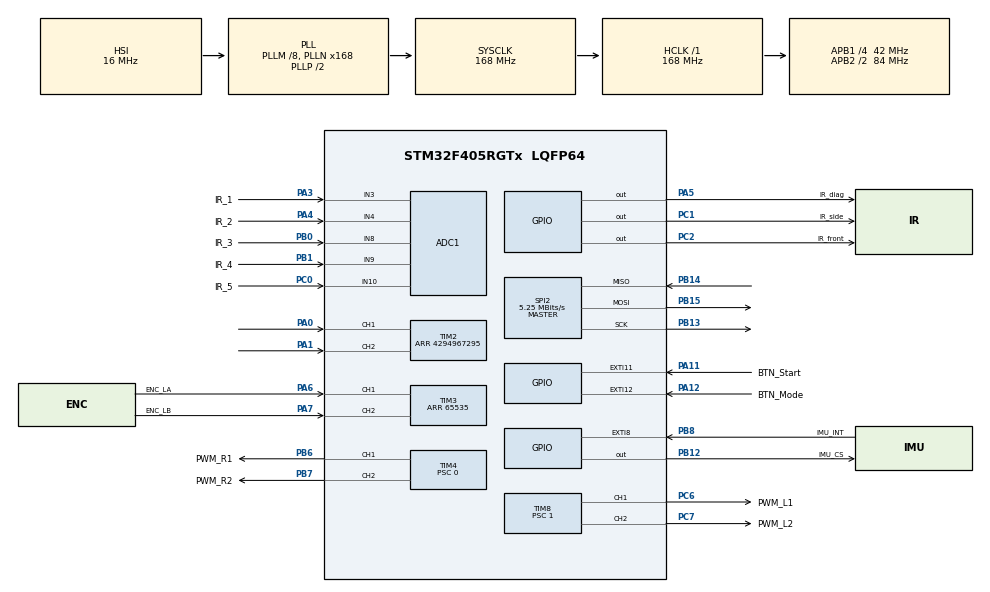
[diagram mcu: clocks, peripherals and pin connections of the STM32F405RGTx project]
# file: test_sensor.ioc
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ADC1.Channel-0\#ChannelRegularConversion=ADC_CHANNEL_3
ADC1.Channel-1\#ChannelRegularConversion=ADC_CHANNEL_4
ADC1.Channel-2\#ChannelRegularConversion=ADC_CHANNEL_8
ADC1.Channel-3\#ChannelRegularConversion=ADC_CHANNEL_9
ADC1.Channel-4\#ChannelRegularConversion=ADC_CHANNEL_10
ADC1.ClockPrescaler=ADC_CLOCK_SYNC_PCLK_DIV4
ADC1.ContinuousConvMode=ENABLE
ADC1.DMAContinuousRequests=ENABLE
ADC1.EOCSelection=ADC_EOC_SEQ_CONV
ADC1.NbrOfConversion=5
ADC1.NbrOfConversionFlag=1
ADC1.Rank-0\#ChannelRegularConversion=1
ADC1.Rank-1\#ChannelRegularConversion=2
ADC1.Rank-2\#ChannelRegularConversion=3
ADC1.Rank-3\#ChannelRegularConversion=4
ADC1.Rank-4\#ChannelRegularConversion=5
ADC1.SamplingTime-0\#ChannelRegularConversion=ADC_SAMPLETIME_56CYCLES
ADC1.SamplingTime-1\#ChannelRegularConversion=ADC_SAMPLETIME_56CYCLES
ADC1.SamplingTime-2\#ChannelRegularConversion=ADC_SAMPLETIME_56CYCLES
ADC1.SamplingTime-3\#ChannelRegularConversion=ADC_SAMPLETIME_56CYCLES
ADC1.SamplingTime-4\#ChannelRegularConversion=ADC_SAMPLETIME_56CYCLES
ADC1.ScanConvMode=ENABLE
ADC1.master=1
Dma.ADC1.0.Direction=DMA_PERIPH_TO_MEMORY
Dma.ADC1.0.FIFOMode=DMA_FIFOMODE_DISABLE
Dma.ADC1.0.Instance=DMA2_Stream0
Dma.ADC1.0.MemDataAlignment=DMA_MDATAALIGN_HALFWORD
Dma.ADC1.0.MemInc=DMA_MINC_ENABLE
Dma.ADC1.0.Mode=DMA_CIRCULAR
Dma.ADC1.0.PeriphDataAlignment=DMA_PDATAALIGN_HALFWORD
Dma.ADC1.0.PeriphInc=DMA_PINC_DISABLE
Dma.ADC1.0.Priority=DMA_PRIORITY_LOW
Dma.Request0=ADC1
Mcu.Family=STM32F4
Mcu.Name=STM32F405RGTx
Mcu.Package=LQFP64
NVIC.DMA2_Stream0_IRQn=true\:0\:0\:false\:false\:true\:false\:true\:true
NVIC.EXTI15_10_IRQn=true\:0\:0\:false\:false\:true\:true\:true\:true
NVIC.EXTI9_5_IRQn=true\:1\:0\:true\:false\:true\:true\:true\:true
NVIC.PriorityGroup=NVIC_PRIORITYGROUP_4
PA0-WKUP.Signal=S_TIM2_CH1_ETR
PA1.Signal=S_TIM2_CH2
PA11.GPIO_Label=BTN_Start
PA11.GPIO_ModeDefaultEXTI=GPIO_MODE_IT_FALLING
PA11.Signal=GPXTI11
PA12.GPIO_Label=BTN_Mode
PA12.GPIO_ModeDefaultEXTI=GPIO_MODE_IT_FALLING
PA12.Signal=GPXTI12
PA13.Mode=Serial_Wire
PA13.Signal=SYS_JTMS-SWDIO
PA14.Mode=Serial_Wire
PA14.Signal=SYS_JTCK-SWCLK
PA3.GPIO_Label=IR_1
PA3.Signal=ADCx_IN3
PA4.GPIO_Label=IR_2
PA4.Signal=ADCx_IN4
PA5.GPIO_Label=IR_diag
PA5.GPIO_PuPd=GPIO_PULLDOWN
PA5.GPIO_Speed=GPIO_SPEED_FREQ_VERY_HIGH
PA5.PinState=GPIO_PIN_RESET
PA5.Signal=GPIO_Output
PA6.GPIO_Label=ENC_LA
PA6.Signal=S_TIM3_CH1
PA7.GPIO_Label=ENC_LB
PA7.Signal=S_TIM3_CH2
PB0.GPIO_Label=IR_3
PB0.Signal=ADCx_IN8
PB1.GPIO_Label=IR_4
PB1.Signal=ADCx_IN9
PB12.GPIO_Label=IMU_CS
PB12.GPIO_PuPd=GPIO_PULLUP
PB12.GPIO_Speed=GPIO_SPEED_FREQ_HIGH
PB12.PinState=GPIO_PIN_SET
PB12.Signal=GPIO_Output
PB13.Mode=Full_Duplex_Master
PB13.Signal=SPI2_SCK
PB14.Mode=Full_Duplex_Master
PB14.Signal=SPI2_MISO
PB15.Mode=Full_Duplex_Master
PB15.Signal=SPI2_MOSI
PB6.GPIO_Label=PWM_R1
PB6.Signal=S_TIM4_CH1
PB7.GPIO_Label=PWM_R2
PB7.Signal=S_TIM4_CH2
PB8.GPIO_Label=IMU_INT
PB8.GPIO_ModeDefaultEXTI=GPIO_MODE_IT_RISING_FALLING
PB8.Signal=GPXTI8
PC0.GPIO_Label=IR_5
PC0.Signal=ADCx_IN10
PC1.GPIO_Label=IR_side
PC1.GPIO_PuPd=GPIO_PULLDOWN
PC1.GPIO_Speed=GPIO_SPEED_FREQ_VERY_HIGH
PC1.PinState=GPIO_PIN_RESET
PC1.Signal=GPIO_Output
PC2.GPIO_Label=IR_front
PC2.GPIO_PuPd=GPIO_PULLDOWN
PC2.GPIO_Speed=GPIO_SPEED_FREQ_VERY_HIGH
PC2.PinState=GPIO_PIN_RESET
PC2.Signal=GPIO_Output
PC6.GPIO_Label=PWM_L1
PC6.Signal=S_TIM8_CH1
PC7.GPIO_Label=PWM_L2
PC7.Signal=S_TIM8_CH2
PH0-OSC_IN.Mode=HSE-External-Oscillator
PH0-OSC_IN.Signal=RCC_OSC_IN
PH1-OSC_OUT.Mode=HSE-External-Oscillator
PH1-OSC_OUT.Signal=RCC_OSC_OUT
ProjectManager.HeapSize=0x200
ProjectManager.StackSize=0x400
ProjectManager.TargetToolchain=CMake
RCC.48MHZClocksFreq_Value=84000000
RCC.AHBFreq_Value=168000000
RCC.APB1CLKDivider=RCC_HCLK_DIV4
RCC.APB1Freq_Value=42000000
RCC.APB1TimFreq_Value=84000000
RCC.APB2CLKDivider=RCC_HCLK_DIV2
RCC.APB2Freq_Value=84000000
RCC.APB2TimFreq_Value=168000000
RCC.CortexFreq_Value=168000000
RCC.HCLKFreq_Value=168000000
RCC.HSE_VALUE=25000000
RCC.HSI_VALUE=16000000
RCC.LSE_VALUE=32768
RCC.PLLM=8
RCC.PLLN=168
RCC.SYSCLKFreq_VALUE=168000000
RCC.SYSCLKSource=RCC_SYSCLKSOURCE_PLLCLK
RCC.VCOOutputFreq_Value=336000000
SH.ADCx_IN10.0=ADC1_IN10,IN10
SH.ADCx_IN3.0=ADC1_IN3,IN3
SH.ADCx_IN4.0=ADC1_IN4,IN4
SH.ADCx_IN8.0=ADC1_IN8,IN8
SH.ADCx_IN9.0=ADC1_IN9,IN9
SH.S_TIM2_CH1_ETR.0=TIM2_CH1,Encoder_Interface
SH.S_TIM2_CH2.0=TIM2_CH2,Encoder_Interface
SH.S_TIM3_CH1.0=TIM3_CH1,Encoder_Interface
SH.S_TIM3_CH2.0=TIM3_CH2,Encoder_Interface
SH.S_TIM4_CH1.0=TIM4_CH1,PWM Generation1 CH1
SH.S_TIM4_CH2.0=TIM4_CH2,PWM Generation2 CH2
SH.S_TIM8_CH1.0=TIM8_CH1,PWM Generation1 CH1
SH.S_TIM8_CH2.0=TIM8_CH2,PWM Generation2 CH2
SPI2.BaudRatePrescaler=SPI_BAUDRATEPRESCALER_8
SPI2.CalculateBaudRate=5.25 MBits/s
SPI2.Direction=SPI_DIRECTION_2LINES
SPI2.Mode=SPI_MODE_MASTER
SPI2.VirtualType=VM_MASTER
TIM2.EncoderMode=TIM_ENCODERMODE_TI12
TIM2.Period=4294967295
TIM3.EncoderMode=TIM_ENCODERMODE_TI12
TIM3.Period=65535
TIM4.Channel-PWM\ Generation1\ CH1=TIM_CHANNEL_1
TIM4.Channel-PWM\ Generation2\ CH2=TIM_CHANNEL_2
TIM4.Period=4199
TIM4.Prescaler=0
TIM8.Channel-PWM\ Generation1\ CH1=TIM_CHANNEL_1
TIM8.Channel-PWM\ Generation2\ CH2=TIM_CHANNEL_2
TIM8.Period=4199
TIM8.Prescaler=1
board=custom

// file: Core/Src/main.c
/* USER CODE BEGIN Header */
/**
  ******************************************************************************
  * @file           : main.c
  * @brief          : Main program body
  ******************************************************************************
  * @attention
  *
  * Copyright (c) 2026 STMicroelectronics.
  * All rights reserved.
  *
  * This software is licensed under terms that can be found in the LICENSE file
  * in the root directory of this software component.
  * If no LICENSE file comes with this software, it is provided AS-IS.
  *
  ******************************************************************************
  */
/* USER CODE END Header */
#include "main.h"
#include "adc.h"
#include "dma.h"
#include "spi.h"
#include "tim.h"
#include "gpio.h"

/* USER CODE BEGIN Includes */
#include "ir_sensor.h"

/* USER CODE END Includes */

void SystemClock_Config(void);

int main(void)
{

  /* MCU Configuration--------------------------------------------------------*/

  /* Reset of all peripherals, Initializes the Flash interface and the Systick. */
  HAL_Init();

  /* Configure the system clock */
  SystemClock_Config();

  /* Initialize all configured peripherals */
  MX_GPIO_Init();
  MX_DMA_Init();
  MX_ADC1_Init();
  MX_SPI2_Init();
  MX_TIM2_Init();
  MX_TIM3_Init();
  MX_TIM4_Init();
  MX_TIM8_Init();
  /* USER CODE BEGIN 2 */
  IR_TestInit();

  /* USER CODE END 2 */

  /* Infinite loop */
  while (1)
  {

    /* USER CODE BEGIN 3 */
    IR_TestLoop();
  }
  /* USER CODE END 3 */
}

void SystemClock_Config(void)
{
  RCC_OscInitTypeDef RCC_OscInitStruct = {0};
  RCC_ClkInitTypeDef RCC_ClkInitStruct = {0};

  /** Configure the main internal regulator output voltage
  */
  __HAL_RCC_PWR_CLK_ENABLE();
  __HAL_PWR_VOLTAGESCALING_CONFIG(PWR_REGULATOR_VOLTAGE_SCALE1);

  /** Initializes the RCC Oscillators according to the specified parameters
  * in the RCC_OscInitTypeDef structure.
  */
  RCC_OscInitStruct.OscillatorType = RCC_OSCILLATORTYPE_HSI;
  RCC_OscInitStruct.HSIState = RCC_HSI_ON;
  RCC_OscInitStruct.HSICalibrationValue = RCC_HSICALIBRATION_DEFAULT;
  RCC_OscInitStruct.PLL.PLLState = RCC_PLL_ON;
  RCC_OscInitStruct.PLL.PLLSource = RCC_PLLSOURCE_HSI;
  RCC_OscInitStruct.PLL.PLLM = 8;
  RCC_OscInitStruct.PLL.PLLN = 168;
  RCC_OscInitStruct.PLL.PLLP = RCC_PLLP_DIV2;
  RCC_OscInitStruct.PLL.PLLQ = 4;
  if (HAL_RCC_OscConfig(&RCC_OscInitStruct) != HAL_OK)
  {
    Error_Handler();
  }

  /** Initializes the CPU, AHB and APB buses clocks
  */
  RCC_ClkInitStruct.ClockType = RCC_CLOCKTYPE_HCLK|RCC_CLOCKTYPE_SYSCLK
                              |RCC_CLOCKTYPE_PCLK1|RCC_CLOCKTYPE_PCLK2;
  RCC_ClkInitStruct.SYSCLKSource = RCC_SYSCLKSOURCE_PLLCLK;
  RCC_ClkInitStruct.AHBCLKDivider = RCC_SYSCLK_DIV1;
  RCC_ClkInitStruct.APB1CLKDivider = RCC_HCLK_DIV4;
  RCC_ClkInitStruct.APB2CLKDivider = RCC_HCLK_DIV2;

  if (HAL_RCC_ClockConfig(&RCC_ClkInitStruct, FLASH_LATENCY_5) != HAL_OK)
  {
    Error_Handler();
  }
}

void Error_Handler(void)
{
  __disable_irq();
  while (1)
  {
  }
}
